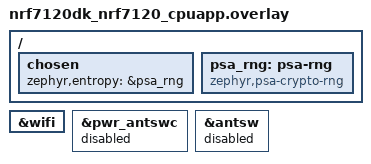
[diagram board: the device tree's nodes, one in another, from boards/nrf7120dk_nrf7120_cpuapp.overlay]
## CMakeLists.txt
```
#
# Copyright (c) 2022 Nordic Semiconductor ASA
#
# SPDX-License-Identifier: LicenseRef-Nordic-5-Clause
#

cmake_minimum_required(VERSION 3.20.0)

find_package(Zephyr REQUIRED HINTS $ENV{ZEPHYR_BASE})
project(nrf_wifi_shell)

if(CONFIG_NRF71_RAW_DATA_TX OR CONFIG_NRF71_PROMISC_DATA_RX)
  target_include_directories(app PUBLIC ${ZEPHYR_BASE}/subsys/net/ip)
endif()

target_sources_ifdef(CONFIG_NRF70_RAW_DATA_TX app PRIVATE src/wifi_raw_tx_pkt_shell.c)
target_sources_ifdef(CONFIG_NRF71_RAW_DATA_TX app PRIVATE src/wifi_raw_tx_pkt_shell.c)

target_sources_ifdef(CONFIG_NRF70_PROMISC_DATA_RX app PRIVATE src/wifi_promiscuous_shell.c)
target_sources_ifdef(CONFIG_NRF71_PROMISC_DATA_RX app PRIVATE src/wifi_promiscuous_shell.c)

target_sources(app PRIVATE src/main.c)
target_sources_ifdef(CONFIG_SAMPLE_SHELL_UART_POWER_BUTTONS app
		     PRIVATE src/uart_power_buttons.c)
```

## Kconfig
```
#
# Copyright (c) 2024 Nordic Semiconductor
#
# SPDX-License-Identifier: LicenseRef-Nordic-5-Clause
#

menu "Nordic Shell sample"

if NET_BUF_FIXED_DATA_SIZE

config NET_BUF_DATA_SIZE
	default 1100

endif

# Configure variable network buffer pool sizes for TX and RX
if NET_BUF_VARIABLE_DATA_SIZE

# nRF52 and nRF54 Series targets have less memory
# so smaller pool sizes are recommended for these targets.
config NET_PKT_BUF_TX_DATA_POOL_SIZE
	default 50000 if SOC_NRF54LM20A || SOC_NRF54LM20B
	default 40000 if SOC_SERIES_NRF54H
	default 35000 if !SOC_SERIES_NRF52 && !SOC_SERIES_NRF54L && BUILD_WITH_TFM
	default 50000 if !SOC_SERIES_NRF52 && !SOC_SERIES_NRF54L

config NET_PKT_BUF_RX_DATA_POOL_SIZE
	default 20000 if SOC_NRF54LM20A || SOC_NRF54LM20B
	default 20000 if !SOC_SERIES_NRF52 && !SOC_SERIES_NRF54L

endif

config SAMPLE_SHELL_UART_POWER_BUTTONS
	bool "Button control of console UART for power measurement"
	depends on DK_LIBRARY
	depends on NRF71_IDLE_POWER
	help
	  On boards with DK buttons, button 1 suspends the console UART and
	  button 2 resumes it. Use while measuring System ON idle current.

source "Kconfig.zephyr"

endmenu
```

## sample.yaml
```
sample:
  description: Wi-Fi shell sample application
  name: Wi-Fi shell
tests:
  sample.nrf7002.shell:
    sysbuild: true
    build_only: true
    integration_platforms:
      - nrf7002dk/nrf5340/cpuapp
    platform_allow: nrf7002dk/nrf5340/cpuapp
    tags:
      - ci_build
      - sysbuild
      - ci_samples_wifi
  # Disable optional features to reduce memory usage
  sample.nrf7002.shell.disable_adv_features:
    sysbuild: true
    build_only: true
    extra_args: -DCONFIG_WIFI_NM_WPA_SUPPLICANT_ADVANCED_FEATURES=n
    integration_platforms:
      - nrf7002dk/nrf5340/cpuapp
    platform_allow: nrf7002dk/nrf5340/cpuapp
    tags:
      - ci_build
      - sysbuild
      - ci_samples_wifi
  sample.nrf7001.shell:
    sysbuild: true
    build_only: true
    integration_platforms:
      - nrf7002dk/nrf5340/cpuapp/nrf7001
    platform_allow: nrf7002dk/nrf5340/cpuapp/nrf7001
    tags:
      - ci_build
      - sysbuild
      - ci_samples_wifi
  sample.nrf7002_eks.shell:
    sysbuild: true
    build_only: true
    extra_args: SHIELD=nrf7002ek
    integration_platforms:
      - nrf5340dk/nrf5340/cpuapp
    platform_allow:
      - nrf5340dk/nrf5340/cpuapp
      - nrf52840dk/nrf52840
    tags:
      - ci_build
      - sysbuild
      - ci_samples_wifi
  sample.nrf7000_eks.shell:
    sysbuild: true
    build_only: true
    extra_args:
      - SHIELD=nrf7002ek_nrf7000
      - CONFIG_WIFI_NM_WPA_SUPPLICANT=n
      - SB_CONFIG_WIFI_NRF70_SCAN_ONLY=y
      - CONFIG_NET_CONNECTION_MANAGER=n
    integration_platforms:
      - nrf5340dk/nrf5340/cpuapp
      - nrf52840dk/nrf52840
    platform_allow:
      - nrf5340dk/nrf5340/cpuapp
      - nrf52840dk/nrf52840
    tags:
      - ci_build
      - sysbuild
      - ci_samples_wifi
  sample.nrf7001_eks.shell:
    sysbuild: true
    build_only: true
    extra_args: SHIELD=nrf7002ek_nrf7001
    integration_platforms:
      - nrf52840dk/nrf52840
    platform_allow:
      - nrf5340dk/nrf5340/cpuapp
      - nrf52840dk/nrf52840
    tags:
      - ci_build
      - sysbuild
      - ci_samples_wifi
  sample.nrf7002_eks_cpunet.shell:
    sysbuild: true
    build_only: true
    extra_args:
      - SHIELD=nrf7002ek
      - CONFIG_SOC_NRF53_CPUNET_ENABLE=y
    integration_platforms:
      - nrf5340dk/nrf5340/cpuapp
    platform_allow: nrf5340dk/nrf5340/cpuapp
    tags:
      - ci_build
      - sysbuild
      - ci_samples_wifi
  sample.nrf7000_eks_cpunet.shell:
    sysbuild: true
    build_only: true
    extra_args:
      - SHIELD=nrf7002ek_nrf7000
      - CONFIG_SOC_NRF53_CPUNET_ENABLE=y
      - CONFIG_WIFI_NM_WPA_SUPPLICANT=n
      - SB_CONFIG_WIFI_NRF70_SCAN_ONLY=y
      - CONFIG_NET_CONNECTION_MANAGER=n
    integration_platforms:
      - nrf5340dk/nrf5340/cpuapp
    platform_allow: nrf5340dk/nrf5340/cpuapp
    tags:
      - ci_build
      - sysbuild
      - ci_samples_wifi
  sample.nrf7001_eks_cpunet.shell:
    sysbuild: true
    build_only: true
    extra_args:
      - SHIELD=nrf7002ek_nrf7001
      - CONFIG_SOC_NRF53_CPUNET_ENABLE=y
    integration_platforms:
      - nrf5340dk/nrf5340/cpuapp
    platform_allow: nrf5340dk/nrf5340/cpuapp
    tags:
      - ci_build
      - sysbuild
      - ci_samples_wifi
  sample.nrf7002.shell.zperf:
    sysbuild: true
    build_only: true
    extra_args: EXTRA_CONF_FILE=overlay-zperf.conf
    integration_platforms:
      - nrf7002dk/nrf5340/cpuapp
    platform_allow: nrf7002dk/nrf5340/cpuapp
    tags:
      - ci_build
      - sysbuild
      - ci_samples_wifi
  sample.nrf7001.shell.zperf:
    sysbuild: true
    build_only: true
    extra_args: EXTRA_CONF_FILE=overlay-zperf.conf
    integration_platforms:
      - nrf7002dk/nrf5340/cpuapp/nrf7001
    platform_allow: nrf7002dk/nrf5340/cpuapp/nrf7001
    tags:
      - ci_build
      - sysbuild
      - ci_samples_wifi
  sample.nrf7002.shell.wpa_cli:
    sysbuild: true
    build_only: true
    extra_args: CONFIG_WPA_CLI=y
    integration_platforms:
      - nrf7002dk/nrf5340/cpuapp
    platform_allow: nrf7002dk/nrf5340/cpuapp
    tags:
      - ci_build
      - sysbuild
      - ci_samples_wifi
  sample.nrf7001.shell.wpa_cli:
    sysbuild: true
    build_only: true
    extra_args: CONFIG_WPA_CLI=y
    integration_platforms:
      - nrf7002dk/nrf5340/cpuapp/nrf7001
    platform_allow: nrf7002dk/nrf5340/cpuapp/nrf7001
    tags:
      - ci_build
      - sysbuild
      - ci_samples_wifi
  sample.nrf7002.shell.scan_only_7002:
    sysbuild: true
    build_only: true
    extra_args:
      - EXTRA_CONF_FILE=overlay-scan-only.conf
      - SB_CONFIG_WIFI_NRF70_SCAN_ONLY=y
    integration_platforms:
      - nrf7002dk/nrf5340/cpuapp
    platform_allow: nrf7002dk/nrf5340/cpuapp
    tags:
      - ci_build
      - sysbuild
      - ci_samples_wifi
  sample.nrf7000.shell.scan_only_91:
    sysbuild: true
    build_only: true
    extra_args:
      - EXTRA_CONF_FILE=overlay-scan-only.conf
      - SHIELD=nrf7002ek_nrf7000
      - CONFIG_TFM_PROFILE_TYPE_MINIMAL=y
      - CONFIG_WIFI_NM_WPA_SUPPLICANT=n
      - SB_CONFIG_WIFI_NRF70_SCAN_ONLY=y
    integration_platforms:
      - nrf9160dk/nrf9160/ns
      - nrf9161dk/nrf9161/ns
    platform_allow:
      - nrf9160dk/nrf9160/ns
      - nrf9161dk/nrf9161/ns
      - nrf9151dk/nrf9151/ns
    tags:
      - ci_build
      - sysbuild
      - ci_samples_wifi
  sample.nrf7002.shell.scan_only_thingy91x:
    sysbuild: true
    build_only: true
    extra_args:
      - EXTRA_CONF_FILE=overlay-scan-only.conf
      - SB_CONFIG_WIFI_NRF70_SCAN_ONLY=y
    platform_allow:
      - thingy91x/nrf9151/ns
    tags:
      - ci_build
      - sysbuild
      - ci_samples_wifi
  sample.nrf7002.shell.full_stack_thingy91x:
    sysbuild: true
    build_only: true
    platform_allow:
      - thingy91x/nrf5340/cpuapp
    tags:
      - ci_build
      - sysbuild
      - ci_samples_wifi
  sample.nrf7002.shell.otbr:
    sysbuild: true
    build_only: true
    extra_args:
      - EXTRA_CONF_FILE=overlay-openthread.conf
      - SB_CONFIG_NETCORE_IPC_RADIO=y
      - SB_CONFIG_NETCORE_IPC_RADIO_IEEE802154=y
    integration_platforms:
      - nrf7002dk/nrf5340/cpuapp
    platform_allow: nrf7002dk/nrf5340/cpuapp
    tags:
      - ci_build
      - sysbuild
      - ci_samples_wifi
  sample.nrf7002_ns.shell:
    sysbuild: true
    build_only: true
    platform_allow: nrf7002dk/nrf5340/cpuapp/ns
    tags:
      - sysbuild
      - ci_samples_wifi
  sample.nrf7002_eb.thingy53.shell:
    sysbuild: true
    build_only: true
    extra_args:
      - shell_SHIELD=nrf7002eb
      - CONFIG_SOC_NRF53_CPUNET_ENABLE=y
    integration_platforms:
      - thingy53/nrf5340/cpuapp
    platform_allow: thingy53/nrf5340/cpuapp
    tags:
      - ci_build
      - sysbuild
      - ci_samples_wifi
  sample.qspi.ext_flash_xip:
    sysbuild: true
    build_only: true
    extra_args:
      - shell_SHIELD=nrf7002ek
      - SB_CONFIG_WIFI_PATCHES_EXT_FLASH_XIP=y
    integration_platforms:
      - nrf5340dk/nrf5340/cpuapp
      - nrf52840dk/nrf52840
    platform_allow:
      - nrf5340dk/nrf5340/cpuapp
      - nrf52840dk/nrf52840
    tags:
      - ci_build
      - sysbuild
      - ci_samples_wifi
  sample.qspi.ext_flash_store:
    sysbuild: true
    build_only: true
    extra_args:
      - shell_SHIELD=nrf7002ek
      - shell_SNIPPET=nrf70-fw-patch-ext-flash
    integration_platforms:
      - nrf5340dk/nrf5340/cpuapp
      - nrf52840dk/nrf52840
    platform_allow:
      - nrf5340dk/nrf5340/cpuapp
      - nrf52840dk/nrf52840
    tags:
      - ci_build
      - sysbuild
      - ci_samples_wifi
  sample.spi.ext_flash_store:
    sysbuild: true
    build_only: true
    extra_args:
      - SNIPPET=nrf70-fw-patch-ext-flash
    integration_platforms:
      - nrf7002dk/nrf5340/cpuapp
    platform_allow:
      - nrf7002dk/nrf5340/cpuapp
    tags:
      - ci_build
      - sysbuild
      - ci_samples_wifi
  sample.nrf7002eb_interposer_p1.nrf7002eb.shell:
    sysbuild: true
    build_only: true
    extra_args:
      - shell_SHIELD="nrf7002eb_interposer_p1;nrf7002eb"
      - shell_SNIPPET=nrf70-wifi
    integration_platforms:
      - nrf54h20dk/nrf54h20/cpuapp
      - nrf54l15dk/nrf54l15/cpuapp
    platform_allow:
      - nrf54h20dk/nrf54h20/cpuapp
      - nrf54l15dk/nrf54l15/cpuapp
    tags:
      - ci_build
      - sysbuild
      - ci_samples_wifi
  sample.nrf7002eb_interposer_p1.nrf7002eb.shell.superset:
    sysbuild: true
    build_only: true
    extra_args:
      - shell_SHIELD="nrf7002eb_interposer_p1;nrf7002eb"
      - shell_SNIPPET=nrf70-wifi
      - EXTRA_CONF_FILE=overlay-zperf.conf
      - CONFIG_NRF70_UTIL=y
      - CONFIG_WPA_CLI=y
      - CONFIG_NET_IPV4_FRAGMENT=y
      - CONFIG_NET_IPV4_FRAGMENT_MAX_PKT=24
      - CONFIG_NRF_WIFI_DATA_HEAP_SIZE=199000
    integration_platforms:
      - nrf54h20dk/nrf54h20/cpuapp
    platform_allow:
      - nrf54h20dk/nrf54h20/cpuapp
    tags:
      - ci_build
      - sysbuild
      - ci_samples_wifi
  sample.nrf7002eb2.shell:
    sysbuild: true
    build_only: true
    extra_args:
      - shell_SHIELD="nrf7002eb2"
      - SNIPPET=nrf70-wifi
    integration_platforms:
      - nrf54l15dk/nrf54l15/cpuapp
    platform_allow:
      - nrf54l15dk/nrf54l15/cpuapp
    tags:
      - ci_build
      - sysbuild
      - ci_samples_wifi
  sample.54lm20dk.nrf7002eb2.shell:
    sysbuild: true
    build_only: true
    extra_args:
      - shell_SHIELD="nrf7002eb2"
    integration_platforms:
      - nrf54lm20dk/nrf54lm20a/cpuapp
      - nrf54lm20dk/nrf54lm20a/cpuapp/ns
      - nrf54lm20dk/nrf54lm20b/cpuapp
      - nrf54lm20dk/nrf54lm20b/cpuapp/ns
    platform_allow:
      - nrf54lm20dk/nrf54lm20a/cpuapp
      - nrf54lm20dk/nrf54lm20a/cpuapp/ns
      - nrf54lm20dk/nrf54lm20b/cpuapp
      - nrf54lm20dk/nrf54lm20b/cpuapp/ns
    tags:
      - ci_build
      - sysbuild
      - ci_samples_wifi
  # Used by QA and also acts as a memory stress test
  sample.nrf7001.superset:
    sysbuild: true
    build_only: true
    extra_args:
      - EXTRA_CONF_FILE=overlay-zperf.conf
      - CONFIG_NRF70_UTIL=y
      - CONFIG_WPA_CLI=y
      - CONFIG_NET_IPV4_FRAGMENT=y
      - CONFIG_NET_IPV4_FRAGMENT_MAX_PKT=24
    integration_platforms:
      - nrf7002dk/nrf5340/cpuapp/nrf7001
    platform_allow: nrf7002dk/nrf5340/cpuapp/nrf7001
    tags:
      - ci_build_superset
      - sysbuild
      - ci_samples_wifi
  # Used by QA and also acts as a memory stress test
  sample.nrf7001_ek.superset:
    sysbuild: true
    build_only: true
    extra_args:
      - SHIELD=nrf7002ek_nrf7001
      - EXTRA_CONF_FILE=overlay-zperf.conf
      - CONFIG_NRF70_UTIL=y
      - CONFIG_WPA_CLI=y
      - CONFIG_NET_IPV4_FRAGMENT=y
      - CONFIG_NET_IPV4_FRAGMENT_MAX_PKT=24
    integration_platforms:
      - nrf5340dk/nrf5340/cpuapp
    platform_allow: nrf5340dk/nrf5340/cpuapp
    tags:
      - ci_build_superset
      - sysbuild
      - ci_samples_wifi
  # Used by QA and also acts as a memory stress test
  sample.nrf7002.superset:
    sysbuild: true
    build_only: true
    extra_args:
      - EXTRA_CONF_FILE=overlay-zperf.conf
      - CONFIG_NRF70_UTIL=y
      - CONFIG_WPA_CLI=y
      - CONFIG_NET_IPV4_FRAGMENT=y
      - CONFIG_NET_IPV4_FRAGMENT_MAX_PKT=24
    integration_platforms:
      - nrf7002dk/nrf5340/cpuapp
    platform_allow: nrf7002dk/nrf5340/cpuapp
    tags:
      - ci_build_superset
      - sysbuild
      - ci_samples_wifi
  # Used by QA and also acts as a memory stress test
  sample.nrf7002_ek.superset:
    sysbuild: true
    build_only: true
    extra_args:
      - SHIELD=nrf7002ek
      - EXTRA_CONF_FILE=overlay-zperf.conf
      - CONFIG_NRF70_UTIL=y
      - CONFIG_WPA_CLI=y
      - CONFIG_NET_IPV4_FRAGMENT=y
      - CONFIG_NET_IPV4_FRAGMENT_MAX_PKT=24
    integration_platforms:
      - nrf5340dk/nrf5340/cpuapp
    platform_allow: nrf5340dk/nrf5340/cpuapp
    tags:
      - ci_build_superset
      - sysbuild
      - ci_samples_wifi
  sample.nrf7002.superset.debug:
    sysbuild: true
    build_only: true
    extra_args:
      - shell_SNIPPET="nrf70-driver-verbose-debug;wpa-supplicant-debug"
      - EXTRA_CONF_FILE=overlay-zperf.conf
      - CONFIG_NRF70_UTIL=y
      - CONFIG_WPA_CLI=y
      - CONFIG_NET_IPV4_FRAGMENT=y
      - CONFIG_NET_IPV4_FRAGMENT_MAX_PKT=24
    integration_platforms:
      - nrf7002dk/nrf5340/cpuapp
    platform_allow: nrf7002dk/nrf5340/cpuapp
    tags:
      - ci_build_superset
      - sysbuild
      - ci_samples_wifi
  sample.nrf7002.enterprise_mode:
    sysbuild: true
    build_only: true
    extra_args: shell_SNIPPET=nordic-wifi-enterprise
    integration_platforms:
      - nrf7002dk/nrf5340/cpuapp
    platform_allow: nrf7002dk/nrf5340/cpuapp
    tags:
      - ci_build
      - sysbuild
      - ci_samples_wifi
  sample.nrf7002.ap:
    sysbuild: true
    build_only: true
    extra_args: shell_SNIPPET=wifi-sap
    integration_platforms:
      - nrf7002dk/nrf5340/cpuapp
    platform_allow: nrf7002dk/nrf5340/cpuapp
    tags:
      - ci_build
      - sysbuild
      - ci_samples_wifi
  sample.nrf7002.with_overlay_raw_tx_packet:
    sysbuild: true
    build_only: true
    extra_args:
      - shell_SNIPPET=wifi-raw-tx
      - SB_CONFIG_WIFI_NRF70_SYSTEM_WITH_RAW_MODES=y
    integration_platforms:
      - nrf7002dk/nrf5340/cpuapp
    platform_allow: nrf7002dk/nrf5340/cpuapp
    tags:
      - ci_build
      - sysbuild
      - ci_samples_wifi
  sample.nrf7002.with_overlay_monitor:
    sysbuild: true
    build_only: true
    extra_args:
      - shell_SNIPPET=wifi-monitor-mode
      - SB_CONFIG_WIFI_NRF70_SYSTEM_WITH_RAW_MODES=y
    integration_platforms:
      - nrf7002dk/nrf5340/cpuapp
    platform_allow: nrf7002dk/nrf5340/cpuapp
    tags:
      - ci_build
      - sysbuild
      - ci_samples_wifi
  sample.nrf7002.promiscuous_mode:
    sysbuild: true
    build_only: true
    extra_args:
      - shell_SNIPPET=wifi-promiscuous-mode
      - SB_CONFIG_WIFI_NRF70_SYSTEM_WITH_RAW_MODES=y
    integration_platforms:
      - nrf7002dk/nrf5340/cpuapp
    platform_allow: nrf7002dk/nrf5340/cpuapp
    tags:
      - ci_build
      - sysbuild
      - ci_samples_wifi
  sample.nrf7001.promiscuous_mode_7001:
    sysbuild: true
    build_only: true
    extra_args:
      - shell_SNIPPET=wifi-promiscuous-mode
      - SB_CONFIG_WIFI_NRF70_SYSTEM_WITH_RAW_MODES=y
    integration_platforms:
      - nrf7002dk/nrf5340/cpuapp/nrf7001
    platform_allow: nrf7002dk/nrf5340/cpuapp/nrf7001
    tags:
      - ci_build
      - sysbuild
      - ci_samples_wifi
  sample.nrf54l15.softap.superset:
    sysbuild: true
    build_only: true
    extra_args:
      - softap_SHIELD="nrf7002eb_interposer_p1;nrf7002eb"
      - softap_SNIPPET=nrf70-wifi
      - CONFIG_HEAP_MEM_POOL_IGNORE_MIN=n
    integration_platforms:
      - nrf54l15dk/nrf54l15/cpuapp
    platform_allow:
      - nrf54l15dk/nrf54l15/cpuapp
    tags:
      - ci_build
      - sysbuild
      - ci_samples_wifi
  sample.nrf7120.shell:
    sysbuild: true
    build_only: true
    extra_args:
      # sysbuild by default is nRF70, to avoid Kconfig warns disable it
      - SB_CONFIG_WIFI_NRF70=n
    integration_platforms:
      - nrf7120dk/nrf7120/cpuapp
      - nrf7120dk/nrf7120/cpuapp/ns
    platform_allow:
      - nrf7120dk/nrf7120/cpuapp
      - nrf7120dk/nrf7120/cpuapp/ns
    tags:
      - ci_build
      - sysbuild
      - ci_samples_nrf71_wifi
  sample.nrf7120.shell.ap:
    sysbuild: true
    build_only: true
    extra_args:
      - SB_CONFIG_WIFI_NRF70=n
      - shell_SNIPPET=wifi-sap
    integration_platforms:
      - nrf7120dk/nrf7120/cpuapp
    platform_allow:
      - nrf7120dk/nrf7120/cpuapp
    tags:
      - ci_build
      - sysbuild
      - ci_samples_nrf71_wifi
  sample.nrf7120.shell.monitor:
    sysbuild: true
    build_only: true
    extra_args:
      - SB_CONFIG_WIFI_NRF70=n
      - shell_SNIPPET=wifi-monitor-mode
    integration_platforms:
      - nrf7120dk/nrf7120/cpuapp
    platform_allow:
      - nrf7120dk/nrf7120/cpuapp
    tags:
      - ci_build
      - sysbuild
      - ci_samples_nrf71_wifi
  sample.nrf7120.shell.promiscuous:
    sysbuild: true
    build_only: true
    extra_args:
      - SB_CONFIG_WIFI_NRF70=n
      - shell_SNIPPET=wifi-promiscuous-mode
    integration_platforms:
      - nrf7120dk/nrf7120/cpuapp
    platform_allow:
      - nrf7120dk/nrf7120/cpuapp
    tags:
      - ci_build
      - sysbuild
      - ci_samples_nrf71_wifi
  sample.nrf7120.shell.raw_tx:
    sysbuild: true
    build_only: true
    extra_args:
      - SB_CONFIG_WIFI_NRF70=n
      - shell_SNIPPET=wifi-raw-tx
    integration_platforms:
      - nrf7120dk/nrf7120/cpuapp
    platform_allow:
      - nrf7120dk/nrf7120/cpuapp
    tags:
      - ci_build
      - sysbuild
      - ci_samples_nrf71_wifi
  sample.nrf7120.shell.p2p:
    sysbuild: true
    build_only: true
    extra_args:
      - SB_CONFIG_WIFI_NRF70=n
      - shell_SNIPPET:STRING=wifi-p2p
      - CONFIG_NET_DHCPV4_SERVER=y
    platform_allow:
      - nrf7120dk/nrf7120/cpuapp
    # Fails to link: Wi-Fi patch region overlaps Zephyr build on nrf7120dk
    platform_exclude:
      - nrf7120dk/nrf7120/cpuapp
    tags:
      - ci_build
      - sysbuild
      - ci_samples_nrf71_wifi
  sample.nrf7002.shell.wpa3_psa:
    build_only: true
    extra_args:
      - CONFIG_HOSTAP_CRYPTO_WPA3_PSA=y
      - CONFIG_HOSTAP_CRYPTO_ALT_PSA=y
    integration_platforms:
      - nrf7002dk/nrf5340/cpuapp
    platform_allow: nrf7002dk/nrf5340/cpuapp
    tags:
      - ci_build
      - sysbuild
      - ci_samples_wifi
  sample.nrf7120.shell.zperf:
    sysbuild: true
    build_only: true
    extra_args:
      - SB_CONFIG_WIFI_NRF70=n
      - EXTRA_CONF_FILE=nrf71-zperf.conf
    integration_platforms:
      - nrf7120dk/nrf7120/cpuapp
    platform_allow: nrf7120dk/nrf7120/cpuapp
    tags:
      - ci_build
      - sysbuild
      - ci_samples_wifi
  sample.nrf7120.shell.enterprise:
    sysbuild: true
    build_only: true
    extra_args:
      - SB_CONFIG_WIFI_NRF70=n
      - shell_SNIPPET=nordic-wifi-enterprise
    integration_platforms:
      - nrf7120dk/nrf7120/cpuapp
    platform_allow:
      - nrf7120dk/nrf7120/cpuapp
    tags:
      - ci_build
      - sysbuild
      - ci_samples_nrf71_wifi
  sample.nrf7120.superset:
    sysbuild: true
    build_only: true
    extra_args:
      - SB_CONFIG_WIFI_NRF70=n
      - EXTRA_CONF_FILE=nrf71-zperf.conf
      - CONFIG_WPA_CLI=y
      - CONFIG_NET_IPV4_FRAGMENT=y
      - CONFIG_NET_IPV4_FRAGMENT_MAX_PKT=24
    integration_platforms:
      - nrf7120dk/nrf7120/cpuapp
    platform_allow: nrf7120dk/nrf7120/cpuapp
    tags:
      - ci_build_superset
      - sysbuild
      - ci_samples_nrf71_wifi
```

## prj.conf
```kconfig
#
# Copyright (c) 2022 Nordic Semiconductor ASA
#
# SPDX-License-Identifier: LicenseRef-Nordic-5-Clause
#
CONFIG_WIFI=y

# WPA supplicant
CONFIG_WIFI_NM_WPA_SUPPLICANT=y
CONFIG_NET_L2_WIFI_SHELL=y

# Networking
CONFIG_NETWORKING=y
CONFIG_NET_SOCKETS=y
CONFIG_NET_LOG=y
CONFIG_NET_IPV6=y
CONFIG_NET_IPV4=y
CONFIG_NET_UDP=y
CONFIG_NET_TCP=y
CONFIG_NET_DHCPV4=y
CONFIG_DNS_RESOLVER=y

CONFIG_NET_STATISTICS=y
CONFIG_NET_STATISTICS_WIFI=y
CONFIG_NET_STATISTICS_USER_API=y

CONFIG_NET_PKT_RX_COUNT=8
CONFIG_NET_PKT_TX_COUNT=8

# Below section is the primary contributor to SRAM and is currently
# tuned for performance, but this will be revisited in the future.
CONFIG_NET_BUF_RX_COUNT=16
CONFIG_NET_BUF_TX_COUNT=16
CONFIG_NET_TC_TX_COUNT=1

CONFIG_NET_IF_UNICAST_IPV6_ADDR_COUNT=4
CONFIG_NET_IF_MCAST_IPV6_ADDR_COUNT=5
CONFIG_NET_MAX_CONTEXTS=5
CONFIG_NET_CONTEXT_SYNC_RECV=y

CONFIG_INIT_STACKS=y

CONFIG_NET_L2_ETHERNET=y
CONFIG_NET_SHELL=y

# Zephyr NET Connection Manager Connectivity layer.
CONFIG_NET_CONNECTION_MANAGER=y
CONFIG_L2_WIFI_CONNECTIVITY=y
CONFIG_L2_WIFI_CONNECTIVITY_AUTO_CONNECT=y
CONFIG_L2_WIFI_CONNECTIVITY_AUTO_DOWN=n

# Memories
CONFIG_MAIN_STACK_SIZE=5200
CONFIG_SHELL_STACK_SIZE=5400

CONFIG_NET_TX_STACK_SIZE=4096
CONFIG_NET_RX_STACK_SIZE=4096
CONFIG_NET_CONNECTION_MANAGER_MONITOR_STACK_SIZE=5000

# Debugging
CONFIG_STACK_SENTINEL=y
CONFIG_DEBUG_COREDUMP=y
CONFIG_DEBUG_COREDUMP_BACKEND_LOGGING=y
CONFIG_DEBUG_COREDUMP_MEMORY_DUMP_MIN=y
CONFIG_SHELL_CMDS_RESIZE=n
#CONFIG_DEBUG=y
CONFIG_WIFI_NM_WPA_SUPPLICANT_LOG_LEVEL_INF=y

# Kernel options
CONFIG_ENTROPY_GENERATOR=y
CONFIG_REBOOT=y

# Logging
CONFIG_LOG=y
CONFIG_PRINTK=y
CONFIG_SHELL=y
CONFIG_SHELL_GETOPT=y
CONFIG_DEVICE_SHELL=y
CONFIG_POSIX_TIMERS=y
CONFIG_DATE_SHELL=y
CONFIG_NET_CONFIG_AUTO_INIT=n
CONFIG_POSIX_API=y

CONFIG_WIFI_CREDENTIALS=y
CONFIG_FLASH=y
CONFIG_FLASH_PAGE_LAYOUT=y
CONFIG_FLASH_MAP=y
CONFIG_NVS=y
CONFIG_SETTINGS=y
CONFIG_SETTINGS_NVS=y

# printing of scan results puts pressure on queues in new locking
# design in net_mgmt. So, use a higher timeout for a crowded
# environment.
CONFIG_NET_MGMT_EVENT_QUEUE_TIMEOUT=5000
CONFIG_ZVFS_POLL_MAX=12
CONFIG_NET_MGMT_EVENT_QUEUE_SIZE=16
CONFIG_MBEDTLS_HEAP_SIZE=32768
```

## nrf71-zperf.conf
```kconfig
CONFIG_NET_ZPERF=y
CONFIG_NET_ZPERF_SERVER=y
# Zperf TCP=6, UDP=2, Others=1
CONFIG_ZVFS_POLL_MAX=20
# Sockets: select + poll take up more stack
CONFIG_MAIN_STACK_SIZE=5200
CONFIG_SHELL_STACK_SIZE=5200
CONFIG_NET_MGMT_EVENT_STACK_SIZE=4600

# Optimized networking settings for performance
CONFIG_NET_PKT_RX_COUNT=28
CONFIG_NET_PKT_TX_COUNT=27
CONFIG_NET_BUF_RX_COUNT=28
CONFIG_NET_BUF_TX_COUNT=54
CONFIG_HEAP_MEM_POOL_SIZE=40144
CONFIG_NRF_WIFI_DATA_HEAP_SIZE=199856

# To enable optimization configuration options
CONFIG_PICOLIBC_USE_MODULE=y
CONFIG_SPEED_OPTIMIZATIONS=y
CONFIG_CACHE_MANAGEMENT=y

# Necessary for zperf_tcp_receiver.c
CONFIG_NET_CONFIG_SETTINGS=y
CONFIG_NET_CONFIG_INIT_TIMEOUT=0

# Zephyr NET Connection Manager Connectivity layer.
CONFIG_NET_CONNECTION_MANAGER=n

# Consumes more memory
CONFIG_WIFI_CREDENTIALS=n
CONFIG_FLASH=n
CONFIG_NVS=n
CONFIG_SETTINGS=n
CONFIG_NRF71_UTIL=y
CONFIG_SYS_HEAP_RUNTIME_STATS=y

# Disable rate limiting to avoid log flooding (default is drop)
CONFIG_LOG_RATELIMIT=n

# Disabled to avoid pulling in CONFIG_THREAD_RUNTIME_STATS, whose
# per-context-switch overhead reduces throughput.
CONFIG_POSIX_MULTI_PROCESS=n
CONFIG_THREAD_MONITOR=n
CONFIG_TIMESLICING=nCONFIG_THREAD_MONITOR=n
CONFIG_TIMESLICING=n
```

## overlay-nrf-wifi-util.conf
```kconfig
CONFIG_NRF_WIFI_UTIL=y
```

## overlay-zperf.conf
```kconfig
CONFIG_NET_ZPERF=y
CONFIG_POSIX_MAX_FDS=16
# Optimized networking settings for performance
CONFIG_NET_PKT_RX_COUNT=30
CONFIG_NET_PKT_TX_COUNT=26
CONFIG_NET_BUF_RX_COUNT=30
CONFIG_NET_BUF_TX_COUNT=52
CONFIG_HEAP_MEM_POOL_SIZE=230000
CONFIG_NET_BUF_DATA_SIZE=1100
CONFIG_NRF700X_QSPI_LOW_POWER=n
#CONFIG_SPEED_OPTIMIZATIONS=y

# Necessary for zperf_tcp_receiver.c
CONFIG_NET_CONFIG_SETTINGS=y
CONFIG_NET_CONFIG_INIT_TIMEOUT=0

# Consumes more memory
CONFIG_WIFI_CREDENTIALS=n
CONFIG_FLASH=n
CONFIG_NVS=n
CONFIG_SETTINGS=n
CONFIG_NRF700X_UTIL=y
```

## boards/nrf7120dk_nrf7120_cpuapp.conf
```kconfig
#
# Copyright (c) 2026 Nordic Semiconductor
#
# SPDX-License-Identifier: LicenseRef-Nordic-5-Clause
#

# Lower System ON idle current: see lib_nrf71_idle_power. Keep the
# default RAM_RETAIN_FULL tier; RAM_RETAIN_UNUSED_ONLY has been observed
# to cause issues on Wi-Fi builds.
CONFIG_NRF71_IDLE_POWER=y
CONFIG_DK_LIBRARY=y
CONFIG_SAMPLE_SHELL_UART_POWER_BUTTONS=y
```

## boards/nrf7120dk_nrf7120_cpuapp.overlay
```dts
/*
 * Copyright (c) 2026 Nordic Semiconductor ASA
 *
 * SPDX-License-Identifier: LicenseRef-Nordic-5-Clause
 */

/* Enable PSA RNG for entropy and Wi-Fi */
/ {
	chosen {
		zephyr,entropy = &psa_rng;
	};

	psa_rng: psa-rng {
		compatible = "zephyr,psa-crypto-rng";
		status = "okay";
	};
};

&wifi {
	status = "okay";
};



&pwr_antswc {
status = "disabled";
};

&antsw {
status = "disabled";
};
```

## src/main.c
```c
/*
 * Copyright (c) 2022 Nordic Semiconductor ASA
 *
 * SPDX-License-Identifier: LicenseRef-Nordic-5-Clause
 */

/** @file
 * @brief WiFi shell sample main function
 */

#include <zephyr/sys/printk.h>
#include <zephyr/kernel.h>
#if defined(CONFIG_NRFX_CLOCK_HFCLK) &&                                                            \
	(defined(CLOCK_FEATURE_HFCLK_DIVIDE_PRESENT) || NRF_CLOCK_HAS_HFCLK192M)
#include <nrfx_clock_hfclk.h>
#endif
#include <zephyr/device.h>
#include <zephyr/net/net_config.h>

#if defined(CONFIG_SAMPLE_SHELL_UART_POWER_BUTTONS)
int uart_power_buttons_init(void);
#endif

#if defined(CONFIG_USB_DEVICE_STACK) && !defined(CONFIG_BOARD_THINGY91X_NRF5340_CPUAPP)
#define USES_USB_ETH 1
#else
#define USES_USB_ETH 0
#endif

#if USES_USB_ETH
#include <zephyr/usb/usb_device.h>
#endif

#if USES_USB_ETH || defined(CONFIG_SLIP)
static struct in_addr addr = { { { 192, 0, 2, 1 } } };
static struct in_addr mask = { { { 255, 255, 255, 0 } } };
#endif /* CONFIG_USB_DEVICE_STACK || CONFIG_SLIP */

#if USES_USB_ETH
int init_usb(void)
{
	int ret;

	ret = usb_enable(NULL);
	if (ret != 0) {
		printk("Cannot enable USB (%d)", ret);
		return ret;
	}

	return 0;
}
#endif


int main(void)
{
#if defined(CONFIG_NRFX_CLOCK_HFCLK) &&                                                            \
	(defined(CLOCK_FEATURE_HFCLK_DIVIDE_PRESENT) || NRF_CLOCK_HAS_HFCLK192M)
	/* For now hardcode to 128MHz */
	nrfx_clock_hfclk_divider_set(NRF_CLOCK_HFCLK_DIV_1);
#endif
	printk("Starting %s with CPU frequency: %d MHz\n", CONFIG_BOARD, SystemCoreClock/MHZ(1));

#if USES_USB_ETH
	init_usb();

	/* Redirect static IP address to netusb*/
	const struct device *usb_dev = device_get_binding("eth_netusb");
	struct net_if *iface = net_if_lookup_by_dev(usb_dev);

	if (!iface) {
		printk("Cannot find network interface: %s", "eth_netusb");
		return -1;
	}

	net_if_ipv4_addr_add(iface, &addr, NET_ADDR_MANUAL, 0);
	net_if_ipv4_set_netmask_by_addr(iface, &addr, &mask);
#endif

#ifdef CONFIG_SLIP
	const struct device *slip_dev = device_get_binding(CONFIG_SLIP_DRV_NAME);
	struct net_if *slip_iface = net_if_lookup_by_dev(slip_dev);

	if (!slip_iface) {
		printk("Cannot find network interface: %s", CONFIG_SLIP_DRV_NAME);
		return -1;
	}

	net_if_ipv4_addr_add(slip_iface, &addr, NET_ADDR_MANUAL, 0);
	net_if_ipv4_set_netmask_by_addr(slip_iface, &addr, &mask);
#endif /* CONFIG_SLIP */

#ifdef CONFIG_NET_CONFIG_SETTINGS
	/* Without this, DHCPv4 starts on first interface and if that is not Wi-Fi or
	 * only supports IPv6, then its an issue. (E.g., OpenThread)
	 *
	 * So, we start DHCPv4 on Wi-Fi interface always, independent of the ordering.
	 */
	const struct device *dev = DEVICE_DT_GET(DT_CHOSEN(zephyr_wifi));
	struct net_if *wifi_iface = net_if_lookup_by_dev(dev);

	/* As both are Ethernet, we need to set specific interface*/
	net_if_set_default(wifi_iface);

	net_config_init_app(dev, "Initializing network");
#endif

#if defined(CONFIG_SAMPLE_SHELL_UART_POWER_BUTTONS)
	if (uart_power_buttons_init() != 0) {
		printk("UART power buttons init failed\n");
	}
#endif

	return 0;
}
```

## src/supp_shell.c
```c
/*
 * Copyright (c) 2022 Nordic Semiconductor ASA
 *
 * SPDX-License-Identifier: LicenseRef-Nordic-5-Clause
 */

/* @file
 * @brief WPA supplicant shell module
 */

#include <zephyr.h>
#include <stdio.h>
#include <stdlib.h>
#include <shell/shell.h>
#include <init.h>
#include <ctype.h>

#include <net/net_if.h>
#include <net/net_event.h>
#include "common.h"
#include "zephyr_fmac_main.h"
#ifdef CONFIG_WPA_SUPP
#include "zephyr/src/zephyr_supp_api.h"
#include "drivers/driver_zephyr.h"
#include "utils/common.h"
#include "config.h"
#include "wpa_supplicant_i.h"
#endif /* CONFIG_WPA_SUPP */

#define SUPPLICANT_SHELL_MODULE "wpa_cli"

static struct {
	const struct shell *shell;

	union {
		struct {
			uint8_t connecting : 1;
			uint8_t disconnecting : 1;
			uint8_t _unused : 6;
		};
		uint8_t all;
	};
} context;

static uint32_t scan_result;

int cli_main(int argc, const char **argv);
extern struct wpa_supplicant *wpa_s_0;
struct wpa_ssid *ssid_0;

#define MAX_SSID_LEN 32


static void scan_result_cb(struct net_if *iface,
			   int status,
			   struct wifi_scan_result *entry)
{
	if (!iface)
		return;

	if (!entry) {
		if (status) {
			shell_fprintf(context.shell,
				      SHELL_WARNING,
				      "Scan request failed (%d)\n",
				      status);
		} else {
			shell_fprintf(context.shell,
				      SHELL_NORMAL,
				      "Scan request done\n");
		}

		return;
	}

	scan_result++;

	if (scan_result == 1U) {
		shell_fprintf(context.shell,
			      SHELL_NORMAL,
			      "\n%-4s | %-32s %-5s | %-4s | %-4s | %-5s\n", "Num", "SSID",
			      "(len)", "Chan", "RSSI", "Sec");
	}

	shell_fprintf(context.shell,
		      SHELL_NORMAL,
		      "%-4d | %-32s %-5u | %-4u | %-4d | %-5s\n",
		      scan_result,
		      entry->ssid,
		      entry->ssid_length,
		      entry->channel,
		      entry->rssi,
		      (entry->security == WIFI_SECURITY_TYPE_PSK ? "WPA/WPA2" : "Open"));
}


static int cmd_supplicant_scan(const struct shell *shell,
			       size_t argc,
			       const char *argv[])
{
	struct net_if *iface = net_if_get_default();
	const struct device *dev = device_get_binding("wlan0");
	const struct wifi_nrf_dev_ops *dev_ops = dev->api;

	context.shell = shell;

#ifdef CONFIG_WPA_SUPP
	return zephyr_supp_scan("wlan0", scan_result_cb);
#else
	return dev_ops->off_api.disp_scan(dev,
					  scan_result_cb);
#endif
}


#ifdef CONFIG_WPA_SUPP
static int __wifi_args_to_params(size_t argc,
				 const char *argv[],
				 struct wifi_connect_req_params *params)
{
	char *endptr;
	int idx = 1;

	if (argc < 1)
		return -EINVAL;

	/* SSID */
	params->ssid = (char *)argv[0];
	params->ssid_length = strlen(params->ssid);

	/* PSK (optional) */
	if (idx < argc) {
		params->psk = (char *)argv[idx];
		params->psk_length = strlen(argv[idx]);
		params->security = WIFI_SECURITY_TYPE_PSK;
		idx++;

		if ((idx < argc) && (strlen(argv[idx]) <= 2)) {
			params->security = strtol(argv[idx], &endptr, 10);
		}
	} else
		params->security = WIFI_SECURITY_TYPE_NONE;

	return 0;
}

int status_check(int status)
{
	if (status == WPA_COMPLETED){
		wpa_printf(MSG_INFO, "CONNECTED\n");
	} else {
		wpa_printf(MSG_INFO, "FAILED TO CONNECT\n");
	}

	return 0;
}


static int cmd_supplicant_connect(const struct shell *shell,
				  size_t argc,
				  const char *argv[])
{
	static struct wifi_connect_req_params cnx_params;
	struct wifi_connect_req_params *params;
	struct wpa_ssid *ssid = NULL;
	bool pmf = true;
	int status = WPA_DISCONNECTED;
	struct wpa_status_check status_cb;

	if (__wifi_args_to_params(argc - 1,
				  &argv[1],
				  &cnx_params)) {
		shell_help(shell);
		return -ENOEXEC;
	}

	params = &cnx_params;
	status_cb.cb = status_check;

	status = zephyr_supp_connect(params, "wlan0", &status_cb);

	return status;	
}


static int cmd_supplicant(const struct shell *shell,
			  size_t argc,
			  const char *argv[])
{
	return cli_main(argc,
			argv);
}

int parse_proto(const char *value)
{
	int val = 0, last, errors = 0;
	char *start, *end, *buf;

	buf = os_strdup(value);
	if (buf == NULL)
		return -1;
	start = buf;

	while (*start != '\0') {
		while (*start == ' ' || *start == '\t')
			start++;
		if (*start == '\0')
			break;
		end = start;
		while (*end != ' ' && *end != '\t' && *end != '\0')
			end++;
		last = *end == '\0';
		*end = '\0';
		if (os_strcmp(start, "WPA") == 0)
			val |= WPA_PROTO_WPA;
		else if (os_strcmp(start, "RSN") == 0 ||
			 os_strcmp(start, "WPA2") == 0)
			val |= WPA_PROTO_RSN;
		else if (os_strcmp(start, "OSEN") == 0)
			val |= WPA_PROTO_OSEN;
		else {
			shell_fprintf(context.shell,
			      SHELL_ERROR, "invalid proto '%s'",
				   start);
			errors++;
		}

		if (last)
			break;
		start = end + 1;
	}
	os_free(buf);

	return val;
}

int parse_auth_alg(const char *value)
{
	int val = 0, last, errors = 0;
	char *start, *end, *buf;

	buf = os_strdup(value);
	if (buf == NULL)
		return -1;
	start = buf;

	while (*start != '\0') {
		while (*start == ' ' || *start == '\t')
			start++;
		if (*start == '\0')
			break;
		end = start;
		while (*end != ' ' && *end != '\t' && *end != '\0')
			end++;
		last = *end == '\0';
		*end = '\0';
		if (os_strcmp(start, "OPEN") == 0)
			val |= WPA_AUTH_ALG_OPEN;
		else if (os_strcmp(start, "SHARED") == 0)
			val |= WPA_AUTH_ALG_SHARED;
		else if (os_strcmp(start, "LEAP") == 0)
			val |= WPA_AUTH_ALG_LEAP;
		else {
			shell_fprintf(context.shell,
			      SHELL_ERROR, "invalid auth_alg '%s'", start);
			errors++;
		}

		if (last)
			break;
		start = end + 1;
	}
	os_free(buf);

	return val;
}

const char *parse_bssid(const char *txt, u8 *addr)
{
	size_t i;

	for (i = 0; i < ETH_ALEN; i++) {
		int a;

		a = hex2byte(txt);
		if (a < 0)
			return NULL;
		txt += 2;
		addr[i] = a;
		if (i < ETH_ALEN - 1 && *txt++ != ':')
			return NULL;
	}
	return txt;
}

int *parse_int_array(const char *value)
{
	int *freqs;
	size_t used, len;
	const char *pos;

	used = 0;
	len = 10;
	freqs = os_calloc(len + 1, sizeof(int));
	if (freqs == NULL)
		return NULL;

	pos = value;
	while (pos) {
		while (*pos == ' ')
			pos++;
		if (used == len) {
			int *n;
			size_t i;

			n = os_realloc_array(freqs, len * 2 + 1, sizeof(int));
			if (n == NULL) {
				os_free(freqs);
				return NULL;
			}
			for (i = len; i <= len * 2; i++)
				n[i] = 0;
			freqs = n;
			len *= 2;
		}

		freqs[used] = atoi(pos);
		if (freqs[used] == 0)
			break;
		used++;
		pos = os_strchr(pos + 1, ' ');
	}

	return freqs;
}

int parse_key_mgmt(const char *value)
{
	int val = 0, last, errors = 0;
	char *start, *end, *buf;

	buf = os_strdup(value);
	if (buf == NULL)
		return -1;
	start = buf;

	while (*start != '\0') {
		while (*start == ' ' || *start == '\t')
			start++;
		if (*start == '\0')
			break;
		end = start;
		while (*end != ' ' && *end != '\t' && *end != '\0')
			end++;
		last = *end == '\0';
		*end = '\0';
		if (os_strcmp(start, "WPA-PSK") == 0)
			val |= WPA_KEY_MGMT_PSK;
		else if (os_strcmp(start, "WPA-EAP") == 0)
			val |= WPA_KEY_MGMT_IEEE8021X;
		else if (os_strcmp(start, "IEEE8021X") == 0)
			val |= WPA_KEY_MGMT_IEEE8021X_NO_WPA;
		else if (os_strcmp(start, "NONE") == 0)
			val |= WPA_KEY_MGMT_NONE;
		else if (os_strcmp(start, "WPA-NONE") == 0)
			val |= WPA_KEY_MGMT_WPA_NONE;
#ifdef CONFIG_IEEE80211R
		else if (os_strcmp(start, "FT-PSK") == 0)
			val |= WPA_KEY_MGMT_FT_PSK;
		else if (os_strcmp(start, "FT-EAP") == 0)
			val |= WPA_KEY_MGMT_FT_IEEE8021X;
#ifdef CONFIG_SHA384
		else if (os_strcmp(start, "FT-EAP-SHA384") == 0)
			val |= WPA_KEY_MGMT_FT_IEEE8021X_SHA384;
#endif /* CONFIG_SHA384 */
#endif /* CONFIG_IEEE80211R */
		else if (os_strcmp(start, "WPA-PSK-SHA256") == 0)
			val |= WPA_KEY_MGMT_PSK_SHA256;
		else if (os_strcmp(start, "WPA-EAP-SHA256") == 0)
			val |= WPA_KEY_MGMT_IEEE8021X_SHA256;
#ifdef CONFIG_WPS
		else if (os_strcmp(start, "WPS") == 0)
			val |= WPA_KEY_MGMT_WPS;
#endif /* CONFIG_WPS */
#ifdef CONFIG_SAE
		else if (os_strcmp(start, "SAE") == 0)
			val |= WPA_KEY_MGMT_SAE;
		else if (os_strcmp(start, "FT-SAE") == 0)
			val |= WPA_KEY_MGMT_FT_SAE;
#endif /* CONFIG_SAE */
#ifdef CONFIG_HS20
		else if (os_strcmp(start, "OSEN") == 0)
			val |= WPA_KEY_MGMT_OSEN;
#endif /* CONFIG_HS20 */
#ifdef CONFIG_SUITEB
		else if (os_strcmp(start, "WPA-EAP-SUITE-B") == 0)
			val |= WPA_KEY_MGMT_IEEE8021X_SUITE_B;
#endif /* CONFIG_SUITEB */
#ifdef CONFIG_SUITEB192
		else if (os_strcmp(start, "WPA-EAP-SUITE-B-192") == 0)
			val |= WPA_KEY_MGMT_IEEE8021X_SUITE_B_192;
#endif /* CONFIG_SUITEB192 */
#ifdef CONFIG_FILS
		else if (os_strcmp(start, "FILS-SHA256") == 0)
			val |= WPA_KEY_MGMT_FILS_SHA256;
		else if (os_strcmp(start, "FILS-SHA384") == 0)
			val |= WPA_KEY_MGMT_FILS_SHA384;
#ifdef CONFIG_IEEE80211R
		else if (os_strcmp(start, "FT-FILS-SHA256") == 0)
			val |= WPA_KEY_MGMT_FT_FILS_SHA256;
		else if (os_strcmp(start, "FT-FILS-SHA384") == 0)
			val |= WPA_KEY_MGMT_FT_FILS_SHA384;
#endif /* CONFIG_IEEE80211R */
#endif /* CONFIG_FILS */
#ifdef CONFIG_OWE
		else if (os_strcmp(start, "OWE") == 0)
			val |= WPA_KEY_MGMT_OWE;
#endif /* CONFIG_OWE */
#ifdef CONFIG_DPP
		else if (os_strcmp(start, "DPP") == 0)
			val |= WPA_KEY_MGMT_DPP;
#endif /* CONFIG_DPP */
		else {
			shell_fprintf(context.shell,
			      SHELL_ERROR, "invalid key_mgmt '%s'", start);
			errors++;
		}

		if (last)
			break;
		start = end + 1;
	}
	os_free(buf);

	return val;
}
static int cmd_supplicant_enable_network(const struct shell *shell, size_t argc,
			       const char *argv[])
{
	int id;

	if (argc > 2) {
		shell_fprintf(context.shell,
			      SHELL_ERROR, "%s:Incorrect usage.\n", __func__);
		return -1;
	}

	id = atoi(argv[1]);
	return zephyr_supp_enable_network(id);
}

static int cmd_supplicant_select_network(const struct shell *shell, size_t argc,
			       const char *argv[])
{
	int id;

	if (argc > 2) {
		shell_fprintf(context.shell,
			    SHELL_ERROR, "%s:Incorrect usage.\n", __func__);
		return -1;
	}

	id = atoi(argv[1]);
	return zephyr_supp_select_network(id);
}

static int cmd_supplicant_disable_network(const struct shell *shell, size_t argc,
			       const char *argv[])
{
	int id;

	if (argc > 2) {
		shell_fprintf(context.shell,
			      SHELL_ERROR, "%s:Incorrect usage.\n", __func__);
		return -1;
	}

	id = atoi(argv[1]);
	return zephyr_supp_disable_network(id);
}

static int cmd_supplicant_add_network(const struct shell *shell, size_t argc,
			       const char *argv[])
{
	if (argc > 1) {
		shell_fprintf(context.shell,
			      SHELL_ERROR, "%s:Incorrect usage.\n", __func__);
		return -1;
	}

	return zephyr_supp_add_network();
}

static int cmd_supplicant_remove_network(const struct shell *shell, size_t argc,
			       const char *argv[])
{
	const char *value;

	if (argc > 3) {
		shell_fprintf(context.shell,
			      SHELL_ERROR, "%s:Incorrect usage.\n", __func__);
		return -1;
	}

	value = argv[1];
	return zephyr_supp_remove_network(value);
}

static int cmd_supplicant_reassociate(const struct shell *shell, size_t argc,
			       const char *argv[])
{
	return zephyr_supp_reassociate();
}

static int cmd_supplicant_disconnect(const struct shell *shell, size_t argc,
			       const char *argv[])
{
	return zephyr_supp_disconnect();
}

static int cmd_supplicant_set_network(const struct shell *shell, size_t argc,
			       const char *argv[])
{
	int id;
	char *param, *value;
	char ssid[SSID_MAX_LEN] = {'\0'};
	int key_mgmt;
	int pairwise;
	int group;
	int proto;
	int auth_alg;
	uint8_t bssid[ETH_ALEN];
	int *freqs = NULL;

	printf("argc: %d\n", argc);
	if (argc < 3) {
		shell_fprintf(context.shell,
			      SHELL_ERROR, "%s:Incorrect usage.\n", __func__);
		return -1;
	}

	id = atoi(argv[1]);
	param = argv[2];
	value = argv[3];
	if (os_strcmp(param, "ssid") == 0) {
		return zephyr_supp_set_ssid(id, value);
	} else if (os_strcmp(param, "psk") == 0) {
		return zephyr_supp_set_psk(id, value);
	} else if (os_strcmp(param, "key_mgmt") == 0) {
		key_mgmt = parse_key_mgmt(value);
		return zephyr_supp_set_key_mgmt(id, key_mgmt);
	} else if (os_strcmp(param, "pairwise") == 0) {
		pairwise = wpa_parse_cipher(value);
		if (pairwise == -1)
			return -1;
		return zephyr_supp_set_pairwise_cipher(id, pairwise);
	} else if (os_strcmp(param, "group") == 0) {
		group = wpa_parse_cipher(value);
		if (group == -1)
			return -1;
		return zephyr_supp_set_group_cipher(id, group);
	} else if (os_strcmp(param, "proto") == 0) {
		proto = parse_proto(value);
		return zephyr_supp_set_proto(id, proto);
	} else if (os_strcmp(param, "auth_alg") == 0) {
		auth_alg = parse_auth_alg(value);
		return zephyr_supp_set_auth_alg(id, auth_alg);
	} else if (os_strcmp(param, "scan_ssid") == 0) {
		return zephyr_supp_set_scan_ssid(id, atoi(value));
	} else if (os_strcmp(param, "bssid") == 0) {
		if (parse_bssid(value, bssid)) {
			return zephyr_supp_set_bssid(id, bssid);
		} else {
			shell_fprintf(context.shell, SHELL_ERROR,
					"Invalid BSSID '%s'.", value);
			return -1;
		}
	} else if (os_strcmp(param, "scan_freq") == 0) {
		freqs = parse_int_array(value);
		if (freqs == NULL)
			return -1;
		if (freqs[0] == 0) {
			os_free(freqs);
			freqs = NULL;
			return -1;
		}
		return zephyr_supp_set_scan_freq(id, freqs);
	} else if (os_strcmp(param, "ieee80211w") == 0) {
		return zephyr_supp_set_ieee80211w(id, atoi(value));
	}

	return 0;
}

static int cmd_supplicant_set(const struct shell *shell, size_t argc,
			       const char *argv[])
{
	const char *param, *value;
	char ssid[SSID_MAX_LEN] = {'\0'};

	printf("argc: %d\n", argc);
	if (argc < 3) {
		shell_fprintf(context.shell,
			      SHELL_ERROR, "%s:Incorrect usage.\n", __func__);
		return -1;
	}

	param = argv[1];
	value = argv[2];

	if (os_strcmp(param, "country") == 0) {
		return zephyr_supp_set_country(value);
	} else if (os_strcmp(param, "pmf") == 0) {
		return zephyr_supp_set_pmf(value);
	}
	return 0;
}

static int cmd_supplicant_sta_autoconnet(const struct shell *shell, size_t argc,
			       const char *argv[])
{
	int value;

	value = atoi(argv[1]);
	return zephyr_supp_sta_autoconnect(value);
}

static int cmd_supplicant_signal_poll(const struct shell *shell, size_t argc,
			       const char *argv[])
{
	return zephyr_supp_signal_poll();
}

static int cmd_supplicant_status(const struct shell *shell, size_t argc,
			       const char *argv[])
{
	char *status_buf = NULL;
	int buflen = 4096;

	status_buf = os_zalloc(sizeof(char) * buflen);

	if (!status_buf) {
		printf("Failed to allocate memory\n");
		return -1;
	}

	zephyr_supp_status(status_buf, buflen);
	printf("STATUS: %s\n", status_buf);

	os_free(status_buf);

	return 0;
}

#endif /* CONFIG_WPA_SUPP */

SHELL_STATIC_SUBCMD_SET_CREATE(
	wpa_cli_cmds,
	SHELL_CMD(scan,
		  NULL,
		  "Scan AP",
		  cmd_supplicant_scan),
#ifdef CONFIG_WPA_SUPP
	SHELL_CMD(connect,
		  NULL,
		  " \"<SSID>\""
		  "\nPassphrase (optional: valid only for secured SSIDs)>"
		  "\nKEY_MGMT (optional: 0-None, 1-WPA2, 2-WPA2-256, 3-WPA3)",
		  cmd_supplicant_connect),
	SHELL_CMD(add_network,
		  NULL,
		  "\"Add Network network id/number\"",
		  cmd_supplicant_add_network),
	SHELL_CMD(set_network,
		  NULL,
		  "\"Set Network params\"",
		  cmd_supplicant_set_network),
	SHELL_CMD(set,
		  NULL,
		  "\"Set Global params\"",
		  cmd_supplicant_set),
	SHELL_CMD(get,
		  NULL, "\"Get Global params\"",
		  cmd_supplicant),
	SHELL_CMD(enable_network,
		  NULL,
		  "\"Enable Network\"",
		  cmd_supplicant_enable_network),
	SHELL_CMD(remove_network,
		  NULL,
		  "\"Remove Network\"",
		  cmd_supplicant_remove_network),
	SHELL_CMD(get_network,
		  NULL,
		  "\"Get Network\"",
		  cmd_supplicant),
	SHELL_CMD(select_network,
		  NULL,
		  "\"Select Network which will be enabled; rest of the networks will be disabled\"",
		  cmd_supplicant_select_network),
	SHELL_CMD(disable_network,
		  NULL,
		  "\"\"",
		  cmd_supplicant_disable_network),
	SHELL_CMD(disconnect,
		  NULL,
		  "\"\"",
		  cmd_supplicant_disconnect),
	SHELL_CMD(reassociate,
		  NULL,
		  "\"\"",
		  cmd_supplicant_reassociate),
	SHELL_CMD(status,
		  NULL,
		  "\"Get client status\"",
		  cmd_supplicant_status),
	SHELL_CMD(bssid,
		  NULL,
		  "\"Associate with this BSSID\"",
		  cmd_supplicant),
	SHELL_CMD(sta_autoconnect,
		  NULL,
		  "\"\"",
		  cmd_supplicant_sta_autoconnet),
	SHELL_CMD(signal_poll,
		  NULL,
		  "\"\"",
		  cmd_supplicant_signal_poll),
#endif /* CONFIG_WPA_SUPP */
	SHELL_SUBCMD_SET_END);


SHELL_CMD_REGISTER(wpa_cli,
		   &wpa_cli_cmds,
		   "WPA supplicant commands",
		   NULL);


static int supplicant_shell_init(const struct device *unused)
{
	ARG_UNUSED(unused);

	context.shell = NULL;
	context.all = 0U;
	scan_result = 0U;

	return 0;
}


SYS_INIT(supplicant_shell_init,
	 APPLICATION,
	 CONFIG_KERNEL_INIT_PRIORITY_DEFAULT);
```

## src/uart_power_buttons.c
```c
/*
 * Copyright (c) 2026 Nordic Semiconductor ASA
 *
 * SPDX-License-Identifier: LicenseRef-Nordic-5-Clause
 */

#include <dk_buttons_and_leds.h>
#include <nrf71_idle_power.h>
#include <zephyr/kernel.h>
#include <zephyr/sys/printk.h>

static void button_handler(uint32_t button_state, uint32_t has_changed)
{
	if ((has_changed & DK_BTN1_MSK) && (button_state & DK_BTN1_MSK)) {
		nrf71_idle_power_suspend_console();
	} else if ((has_changed & DK_BTN2_MSK) && (button_state & DK_BTN2_MSK)) {
		nrf71_idle_power_resume_console();
		printk("Console UART resumed (Button 2)\n");
	}
}

int uart_power_buttons_init(void)
{
	return dk_buttons_init(button_handler);
}
```
